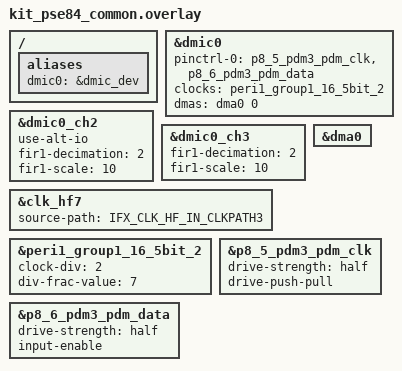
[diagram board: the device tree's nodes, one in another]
/*
 * SPDX-FileCopyrightText: Copyright (c) 2026 Infineon Technologies AG,
 * SPDX-FileCopyrightText: or an affiliate of Infineon Technologies AG. All rights reserved.
 *
 * SPDX-License-Identifier: Apache-2.0
 */

/ {
	aliases {
		dmic0 = &dmic_dev;
	};
};

dmic_dev: &dmic0 {
	pinctrl-0 = <&p8_5_pdm3_pdm_clk &p8_6_pdm3_pdm_data>;
	pinctrl-names = "default";
	clocks = <&peri1_group1_16_5bit_2>;
	status = "okay";

	dmas = <&dma0 0>;
	dma-names = "rx";
};

&dmic0_ch2 {
	status = "okay";
	use-alt-io;
	/* FIR1_DECIM_3: with the default CIC_DECIM_32, this gives a total PDM
	 * oversampling ratio of 96 (1.536 MHz at 16 kHz), matching the mic's
	 * datasheet "Normal mode" clock band.
	 *
	 * fir1-scale lowers the filter output gain to match the larger
	 * accumulator that comes with this oversampling ratio; 10 is the
	 * vendor BSP's own value for this same 96x ratio.
	 */
	fir1-decimation = <2>;
	fir1-scale = <10>;
};

&dmic0_ch3 {
	status = "okay";
	fir1-decimation = <2>;
	fir1-scale = <10>;
};

&dma0 {
	status = "okay";
};

&clk_hf7 {
	status = "okay";
	source-path = <IFX_CLK_HF_IN_CLKPATH3>;
};

&peri1_group1_16_5bit_2 {
	status = "okay";
	clock-div = <2>;
	div-frac-value = <7>;
};

&p8_5_pdm3_pdm_clk {
	drive-strength = "half";
	drive-push-pull;
};

&p8_6_pdm3_pdm_data {
	drive-strength = "half";
	input-enable;
};
